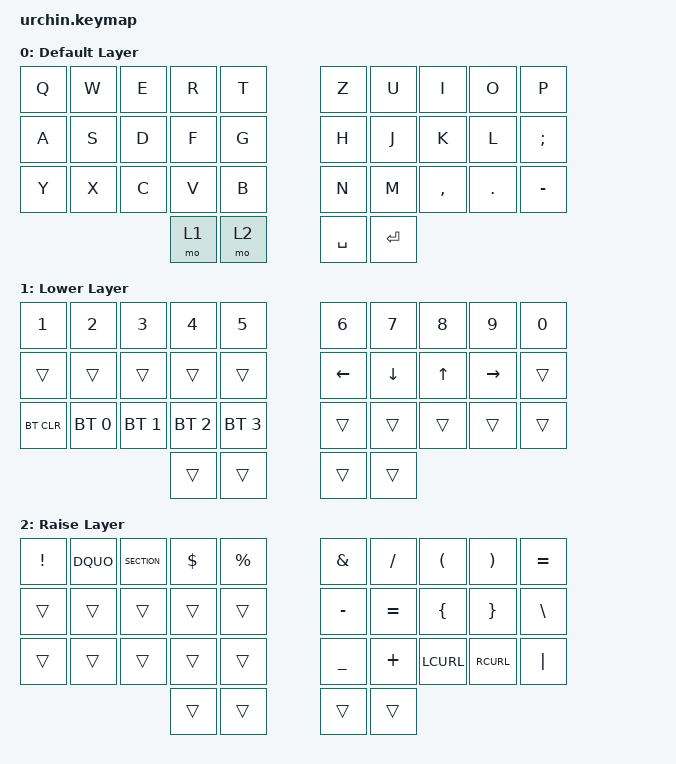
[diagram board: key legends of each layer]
/*
 * German QWERTZ Keymap for Urchin
 *
 * This keymap is configured for a 3x5 matrix with a 2-key thumb cluster on each half.
 *
 * Layers:
 * 0: Base Layer (QWERTZ)
 * 1: Lower Layer (Numbers, Navigation, Bluetooth)
 * 2: Raise Layer (Symbols, Special Characters)
 */

#include <behaviors.dtsi>
#include <dt-bindings/zmk/keys.h>
#include <dt-bindings/zmk/bt.h>

/ {
    keymap {
        compatible = "zmk,keymap";

        default_layer {
            display-name = "Default Layer";
            bindings = <
&kp Q &kp W &kp E &kp R &kp T                  &kp Z &kp U &kp I &kp O &kp P
&kp A &kp S &kp D &kp F &kp G                  &kp H &kp J &kp K &kp L &kp SEMI
&kp Y &kp X &kp C &kp V &kp B                  &kp N &kp M &kp COMMA &kp DOT &kp MINUS
                                  &mo 1    &mo 2          &kp SPACE &kp ENTER
            >;
        };

        lower_layer {
            display-name = "Lower Layer";
            bindings = <
&kp N1   &kp N2   &kp N3   &kp N4   &kp N5                 &kp N6    &kp N7    &kp N8    &kp N9    &kp N0
&trans   &trans   &trans   &trans   &trans                 &kp LEFT  &kp DOWN  &kp UP    &kp RIGHT &trans
&bt BT_CLR &bt BT_SEL <0> &bt BT_SEL <1> &bt BT_SEL <2> &bt BT_SEL <3>      &trans    &trans    &trans    &trans    &trans
                                  &trans   &trans          &trans   &trans
            >;
        };

        raise_layer {
            display-name = "Raise Layer";
            bindings = <
&kp EXCL &kp DQUO &kp SECTION &kp DLLR &kp PRCNT             &kp AMPS  &kp FSLH  &kp LPAR &kp RPAR &kp EQUAL
&trans   &trans   &trans   &trans   &trans                 &kp MINUS &kp EQUAL &kp LBRC  &kp RBRC &kp BSLH
&trans   &trans   &trans   &trans   &trans                 &kp UNDER &kp PLUS  &kp LCURL &kp RCURL &kp PIPE
                                  &trans   &trans          &trans   &trans
            >;
        };
    };
};
